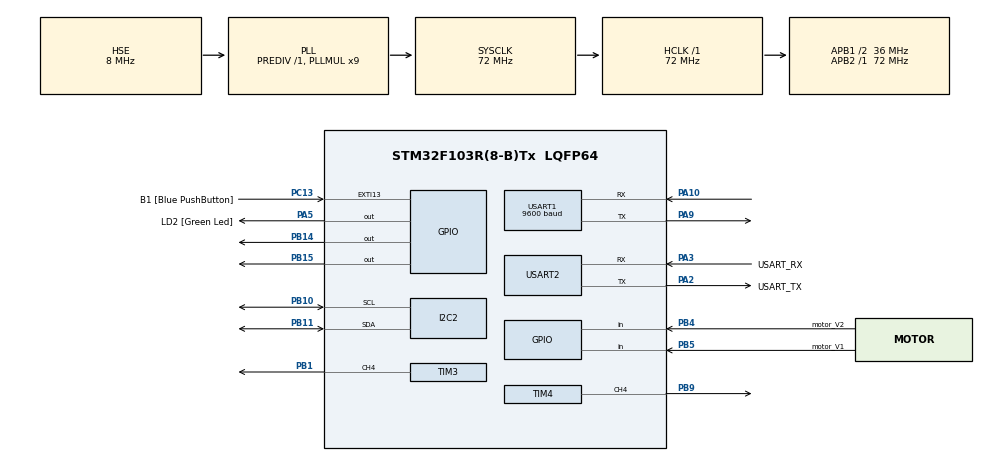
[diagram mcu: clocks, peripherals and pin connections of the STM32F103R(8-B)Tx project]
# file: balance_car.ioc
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Mcu.Family=STM32F1
Mcu.Name=STM32F103R(8-B)Tx
Mcu.Package=LQFP64
NVIC.EXTI15_10_IRQn=true\:0\:0\:false\:false\:true\:true
NVIC.PriorityGroup=NVIC_PRIORITYGROUP_4
PA10.Mode=Asynchronous
PA10.Signal=USART1_RX
PA13.GPIO_Label=TMS
PA13.Mode=Serial_Wire
PA13.Signal=SYS_JTMS-SWDIO
PA14.GPIO_Label=TCK
PA14.Mode=Serial_Wire
PA14.Signal=SYS_JTCK-SWCLK
PA2.GPIO_Label=USART_TX
PA2.GPIO_Mode=GPIO_MODE_AF_PP
PA2.GPIO_PuPd=GPIO_NOPULL
PA2.GPIO_Speed=GPIO_SPEED_FREQ_HIGH
PA2.Mode=Asynchronous
PA2.Signal=USART2_TX
PA3.GPIO_Label=USART_RX
PA3.GPIO_Mode=GPIO_MODE_INPUT
PA3.GPIO_PuPd=GPIO_NOPULL
PA3.GPIO_Speed=GPIO_SPEED_FREQ_LOW
PA3.Mode=Asynchronous
PA3.Signal=USART2_RX
PA5.GPIO_Label=LD2 [Green Led]
PA5.GPIO_ModeDefaultOutputPP=GPIO_MODE_OUTPUT_PP
PA5.GPIO_PuPd=GPIO_NOPULL
PA5.GPIO_Speed=GPIO_SPEED_FREQ_LOW
PA5.Signal=GPIO_Output
PA9.Mode=Asynchronous
PA9.Signal=USART1_TX
PB1.Signal=S_TIM3_CH4
PB10.Mode=I2C
PB10.Signal=I2C2_SCL
PB11.Mode=I2C
PB11.Signal=I2C2_SDA
PB14.Signal=GPIO_Output
PB15.Signal=GPIO_Output
PB3.GPIO_Label=SWO
PB3.Signal=SYS_JTDO-TRACESWO
PB4.GPIO_Label=motor_V2
PB4.Signal=GPIO_Input
PB5.GPIO_Label=motor_V1
PB5.Signal=GPIO_Input
PB9.Signal=S_TIM4_CH4
PC13-TAMPER-RTC.GPIO_Label=B1 [Blue PushButton]
PC13-TAMPER-RTC.GPIO_PuPd=GPIO_NOPULL
PC13-TAMPER-RTC.Signal=GPXTI13
PC14-OSC32_IN.Mode=LSE-External-Oscillator
PC14-OSC32_IN.Signal=RCC_OSC32_IN
PC15-OSC32_OUT.Mode=LSE-External-Oscillator
PC15-OSC32_OUT.Signal=RCC_OSC32_OUT
PD0-OSC_IN.Mode=HSE-External-Clock-Source
PD0-OSC_IN.Signal=RCC_OSC_IN
PD1-OSC_OUT.Mode=HSE-External-Clock-Source
PD1-OSC_OUT.Signal=RCC_OSC_OUT
ProjectManager.HeapSize=0x200
ProjectManager.StackSize=0x400
ProjectManager.TargetToolchain=MDK-ARM V5
RCC.AHBFreq_Value=72000000
RCC.APB1CLKDivider=RCC_HCLK_DIV2
RCC.APB1Freq_Value=36000000
RCC.APB1TimFreq_Value=72000000
RCC.APB2Freq_Value=72000000
RCC.APB2TimFreq_Value=72000000
RCC.HCLKFreq_Value=72000000
RCC.PLLMUL=RCC_PLL_MUL9
RCC.PLLSourceVirtual=RCC_PLLSOURCE_HSE
RCC.RTCClockSelection=RCC_RTCCLKSOURCE_LSE
RCC.SYSCLKFreq_VALUE=72000000
RCC.SYSCLKSource=RCC_SYSCLKSOURCE_PLLCLK
RCC.USBFreq_Value=72000000
SH.S_TIM3_CH4.0=TIM3_CH4,PWM Generation4 CH4
SH.S_TIM4_CH4.0=TIM4_CH4,PWM Generation4 CH4
TIM3.Channel-PWM\ Generation4\ CH4=TIM_CHANNEL_4
TIM3.Period=1999
TIM3.Prescaler=719
TIM4.Channel-PWM\ Generation4\ CH4=TIM_CHANNEL_4
TIM4.Period=1999
TIM4.Prescaler=719
USART1.BaudRate=9600
USART1.VirtualMode=VM_ASYNC
USART2.VirtualMode=VM_ASYNC
VP_TIM3_VS_ClockSourceINT.Mode=Internal
VP_TIM4_VS_ClockSourceINT.Mode=Internal
board=NUCLEO-F103RB

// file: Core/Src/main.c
/**
  ******************************************************************************
  * @file           : main.c
  * @brief          : Main program body
  ******************************************************************************
  ** This notice applies to any and all portions of this file
  * that are not between comment pairs USER CODE BEGIN and
  * USER CODE END. Other portions of this file, whether
  * inserted by the user or by software development tools
  * are owned by their respective copyright owners.
  *
  * COPYRIGHT(c) 2018 STMicroelectronics
  *
  * Redistribution and use in source and binary forms, with or without modification,
  * are permitted provided that the following conditions are met:
  *   1. Redistributions of source code must retain the above copyright notice,
  *      this list of conditions and the following disclaimer.
  *   2. Redistributions in binary form must reproduce the above copyright notice,
  *      this list of conditions and the following disclaimer in the documentation
  *      and/or other materials provided with the distribution.
  *   3. Neither the name of STMicroelectronics nor the names of its contributors
  *      may be used to endorse or promote products derived from this software
  *      without specific prior written permission.
  *
  * THIS SOFTWARE IS PROVIDED BY THE COPYRIGHT HOLDERS AND CONTRIBUTORS "AS IS"
  * AND ANY EXPRESS OR IMPLIED WARRANTIES, INCLUDING, BUT NOT LIMITED TO, THE
  * IMPLIED WARRANTIES OF MERCHANTABILITY AND FITNESS FOR A PARTICULAR PURPOSE ARE
  * DISCLAIMED. IN NO EVENT SHALL THE COPYRIGHT HOLDER OR CONTRIBUTORS BE LIABLE
  * FOR ANY DIRECT, INDIRECT, INCIDENTAL, SPECIAL, EXEMPLARY, OR CONSEQUENTIAL
  * DAMAGES (INCLUDING, BUT NOT LIMITED TO, PROCUREMENT OF SUBSTITUTE GOODS OR
  * SERVICES; LOSS OF USE, DATA, OR PROFITS; OR BUSINESS INTERRUPTION) HOWEVER
  * CAUSED AND ON ANY THEORY OF LIABILITY, WHETHER IN CONTRACT, STRICT LIABILITY,
  * OR TORT (INCLUDING NEGLIGENCE OR OTHERWISE) ARISING IN ANY WAY OUT OF THE USE
  * OF THIS SOFTWARE, EVEN IF ADVISED OF THE POSSIBILITY OF SUCH DAMAGE.
  *
  ******************************************************************************
  */
#include "main.h"
#include "stm32f1xx_hal.h"
#include "i2c.h"
#include "tim.h"
#include "usart.h"
#include "gpio.h"
#include "motor.h"
#include "mpu6500.h"
#include "tsl2561.h"

/* USER CODE BEGIN PV */
extern int blue_key = 0;
extern uint16_t motor_left_step = 0;
extern uint16_t motor_right_step = 0;
/* Private variables ---------------------------------------------------------*/

/* USER CODE END PV */

void SystemClock_Config(void);

/* USER CODE BEGIN PFP */
/* Private function prototypes -----------------------------------------------*/

/* USER CODE END PFP */

/* USER CODE BEGIN 0 */
int fputc(int ch, FILE *f)
{
    HAL_UART_Transmit(&huart2,(uint8_t *)&ch,1,0xff);
    return ch;
}

/* USER CODE END 0 */

int main(void)
{

  /* MCU Configuration----------------------------------------------------------*/

  /* Reset of all peripherals, Initializes the Flash interface and the Systick. */
  HAL_Init();

  /* Configure the system clock */
  SystemClock_Config();

  /* Initialize all configured peripherals */
  MX_GPIO_Init();
  MX_USART2_UART_Init();
  MX_USART1_UART_Init();
  MX_TIM4_Init();
  MX_TIM3_Init();
  MX_I2C2_Init();

  /* Infinite loop */
  while (1)
  {

  /* USER CODE BEGIN 3 */
    // tsl2561_init();
    // lux = tsl2561_get_lux();
    // printf("The luminous flux is %f \n",lux);
    HAL_Delay(10);
    printf("left_step is %d \n right_step is %d \n blue_key is %d \n",motor_left_step,motor_right_step,blue_key);
    // mpu6500_prt();

  }
  /* USER CODE END 3 */

}

void SystemClock_Config(void)
{

  RCC_OscInitTypeDef RCC_OscInitStruct;
  RCC_ClkInitTypeDef RCC_ClkInitStruct;

    /**Initializes the CPU, AHB and APB busses clocks
    */
  RCC_OscInitStruct.OscillatorType = RCC_OSCILLATORTYPE_HSE;
  RCC_OscInitStruct.HSEState = RCC_HSE_BYPASS;
  RCC_OscInitStruct.HSEPredivValue = RCC_HSE_PREDIV_DIV1;
  RCC_OscInitStruct.HSIState = RCC_HSI_ON;
  RCC_OscInitStruct.PLL.PLLState = RCC_PLL_ON;
  RCC_OscInitStruct.PLL.PLLSource = RCC_PLLSOURCE_HSE;
  RCC_OscInitStruct.PLL.PLLMUL = RCC_PLL_MUL9;
  if (HAL_RCC_OscConfig(&RCC_OscInitStruct) != HAL_OK)
  {
    _Error_Handler(__FILE__, __LINE__);
  }

    /**Initializes the CPU, AHB and APB busses clocks
    */
  RCC_ClkInitStruct.ClockType = RCC_CLOCKTYPE_HCLK|RCC_CLOCKTYPE_SYSCLK
                              |RCC_CLOCKTYPE_PCLK1|RCC_CLOCKTYPE_PCLK2;
  RCC_ClkInitStruct.SYSCLKSource = RCC_SYSCLKSOURCE_PLLCLK;
  RCC_ClkInitStruct.AHBCLKDivider = RCC_SYSCLK_DIV1;
  RCC_ClkInitStruct.APB1CLKDivider = RCC_HCLK_DIV2;
  RCC_ClkInitStruct.APB2CLKDivider = RCC_HCLK_DIV1;

  if (HAL_RCC_ClockConfig(&RCC_ClkInitStruct, FLASH_LATENCY_2) != HAL_OK)
  {
    _Error_Handler(__FILE__, __LINE__);
  }

    /**Configure the Systick interrupt time
    */
  HAL_SYSTICK_Config(HAL_RCC_GetHCLKFreq()/1000);

    /**Configure the Systick
    */
  HAL_SYSTICK_CLKSourceConfig(SYSTICK_CLKSOURCE_HCLK);

  /* SysTick_IRQn interrupt configuration */
  HAL_NVIC_SetPriority(SysTick_IRQn, 0, 0);
}

void _Error_Handler(char *file, int line)
{
  while(1)
  {
  }
}

/************************ (C) COPYRIGHT STMicroelectronics *****END OF FILE****/
